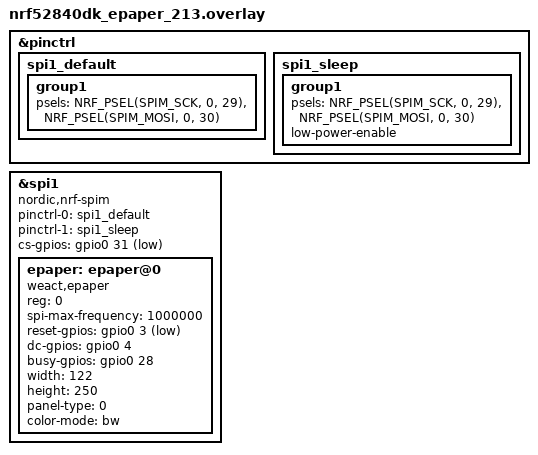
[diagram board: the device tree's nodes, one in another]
/*
 * Copyright (c) 2025 WeAct Studio
 * SPDX-License-Identifier: Apache-2.0
 *
 * Device tree overlay for nRF52840-DK with WeAct 2.13" E-Paper Display
 *
 * Pin connections:
 * - P0.03 -> RES (Reset)
 * - P0.04 -> DC (Data/Command)
 * - P0.28 -> BUSY
 * - P0.31 -> CS (SPI)
 * - P0.29 -> SCK (SPI)
 * - P0.30 -> MOSI (SPI)
 */

&pinctrl {
	spi1_default: spi1_default {
		group1 {
			psels = <NRF_PSEL(SPIM_SCK, 0, 29)>,
				<NRF_PSEL(SPIM_MOSI, 0, 30)>;
		};
	};

	spi1_sleep: spi1_sleep {
		group1 {
			psels = <NRF_PSEL(SPIM_SCK, 0, 29)>,
				<NRF_PSEL(SPIM_MOSI, 0, 30)>;
			low-power-enable;
		};
	};
};

&spi1 {
	compatible = "nordic,nrf-spim";
	status = "okay";
	pinctrl-0 = <&spi1_default>;
	pinctrl-1 = <&spi1_sleep>;
	pinctrl-names = "default", "sleep";
	cs-gpios = <&gpio0 31 GPIO_ACTIVE_LOW>;

	epaper: epaper@0 {
		compatible = "weact,epaper";
		reg = <0>;
		spi-max-frequency = <1000000>;
		reset-gpios = <&gpio0 3 GPIO_ACTIVE_LOW>;
		dc-gpios = <&gpio0 4 GPIO_ACTIVE_HIGH>;
		busy-gpios = <&gpio0 28 GPIO_ACTIVE_HIGH>;
		width = <122>;
		height = <250>;
		panel-type = <0>; /* EPD213_219 */
		color-mode = "bw";
	};
};
